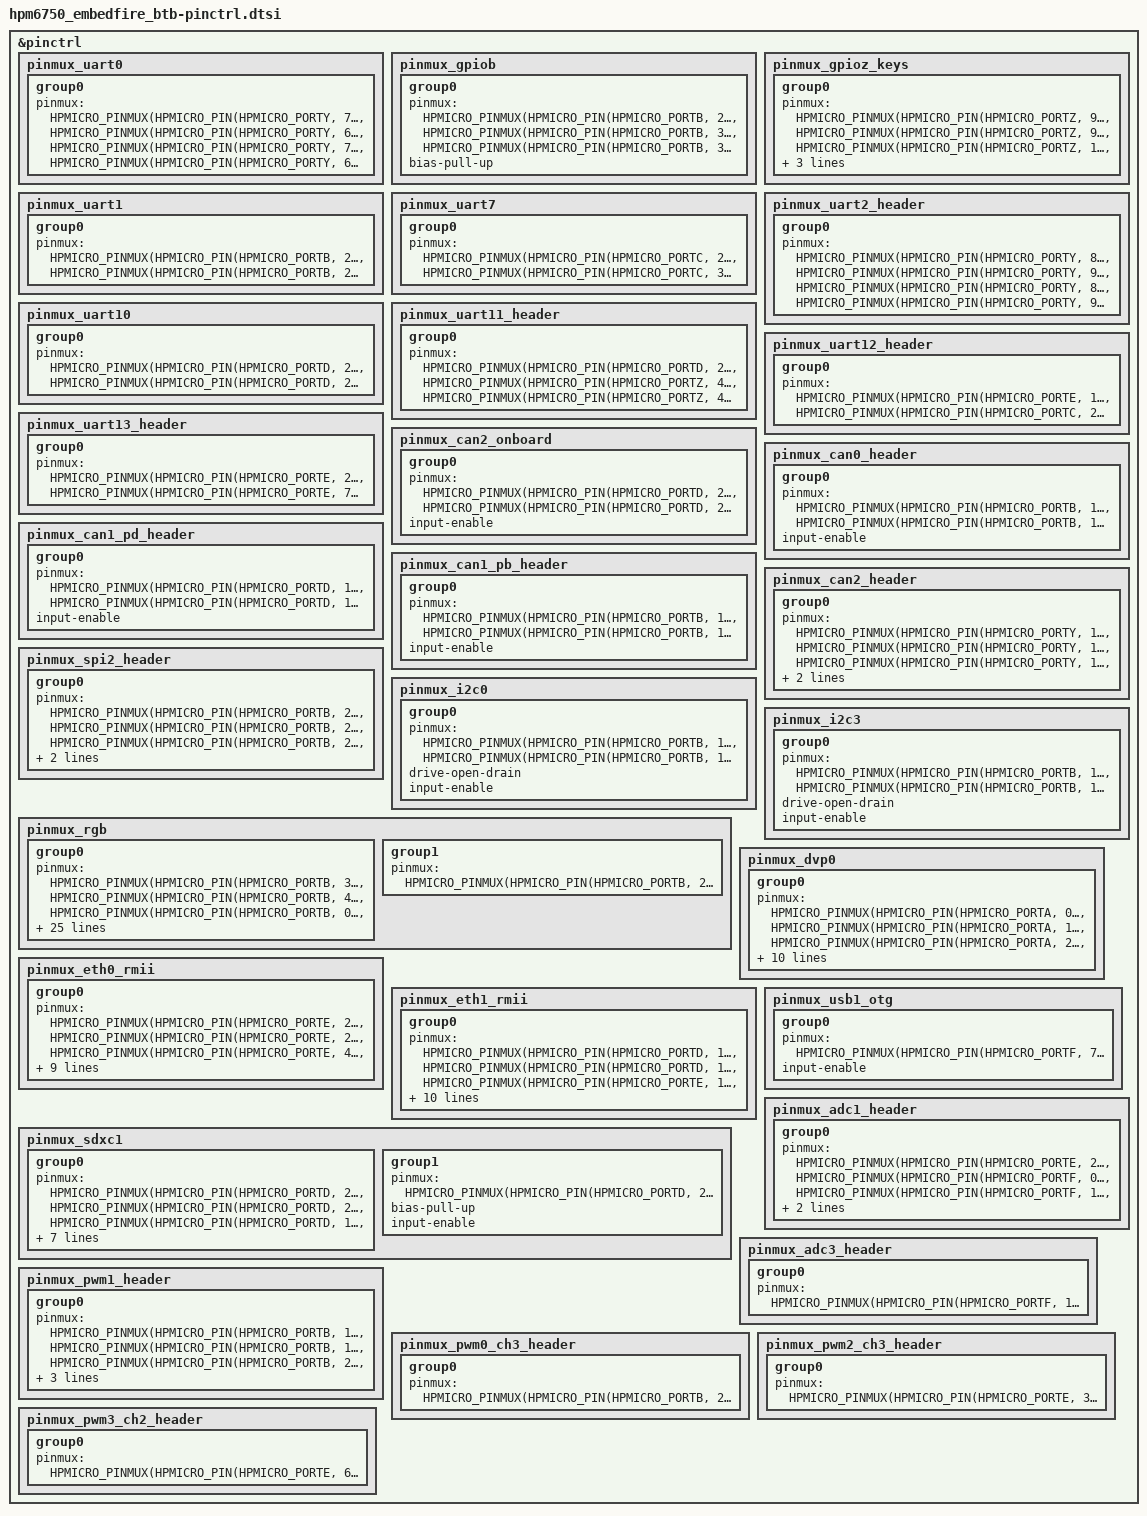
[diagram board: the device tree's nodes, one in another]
/* SPDX-License-Identifier: Apache-2.0 */

#include "dt-bindings/pinctrl/hpmicro-pinctrl-common.h"

&pinctrl {
	pinmux_uart0: pinmux_uart0 {
		group0 {
			pinmux = <HPMICRO_PINMUX(HPMICRO_PIN(HPMICRO_PORTY, 7), IOC_TYPE_IOC, 0, 2)>,
				 <HPMICRO_PINMUX(HPMICRO_PIN(HPMICRO_PORTY, 6), IOC_TYPE_IOC, 0, 2)>,
				 <HPMICRO_PINMUX(HPMICRO_PIN(HPMICRO_PORTY, 7), IOC_TYPE_PIOC, 0, 3)>,
				 <HPMICRO_PINMUX(HPMICRO_PIN(HPMICRO_PORTY, 6), IOC_TYPE_PIOC, 0, 3)>;
		};
	};

	pinmux_gpiob: pinmux_gpiob {
		group0 {
			pinmux = <HPMICRO_PINMUX(HPMICRO_PIN(HPMICRO_PORTB, 29), IOC_TYPE_IOC, 0, 0)>,
				 <HPMICRO_PINMUX(HPMICRO_PIN(HPMICRO_PORTB, 30), IOC_TYPE_IOC, 0, 0)>,
				 <HPMICRO_PINMUX(HPMICRO_PIN(HPMICRO_PORTB, 31), IOC_TYPE_IOC, 0, 0)>;
			bias-pull-up;
		};
	};

	pinmux_gpioz_keys: pinmux_gpioz_keys {
		group0 {
			pinmux = <HPMICRO_PINMUX(HPMICRO_PIN(HPMICRO_PORTZ, 9), IOC_TYPE_IOC, 0, 0)>,
				 <HPMICRO_PINMUX(HPMICRO_PIN(HPMICRO_PORTZ, 9), IOC_TYPE_BIOC, 0, 3)>,
				 <HPMICRO_PINMUX(HPMICRO_PIN(HPMICRO_PORTZ, 11), IOC_TYPE_IOC, 0, 0)>,
				 <HPMICRO_PINMUX(HPMICRO_PIN(HPMICRO_PORTZ, 11), IOC_TYPE_BIOC, 0, 3)>;
			bias-pull-up;
			input-enable;
		};
	};

	pinmux_uart1: pinmux_uart1 {
		group0 {
			pinmux = <HPMICRO_PINMUX(HPMICRO_PIN(HPMICRO_PORTB, 26), IOC_TYPE_IOC, 0, 2)>,
				 <HPMICRO_PINMUX(HPMICRO_PIN(HPMICRO_PORTB, 27), IOC_TYPE_IOC, 0, 2)>;
		};
	};

	pinmux_uart7: pinmux_uart7 {
		group0 {
			pinmux = <HPMICRO_PINMUX(HPMICRO_PIN(HPMICRO_PORTC, 2), IOC_TYPE_IOC, 0, 2)>,
				 <HPMICRO_PINMUX(HPMICRO_PIN(HPMICRO_PORTC, 3), IOC_TYPE_IOC, 0, 2)>;
		};
	};

	pinmux_uart2_header: pinmux_uart2_header {
		group0 {
			pinmux = <HPMICRO_PINMUX(HPMICRO_PIN(HPMICRO_PORTY, 8), IOC_TYPE_IOC, 0, 2)>,
				 <HPMICRO_PINMUX(HPMICRO_PIN(HPMICRO_PORTY, 9), IOC_TYPE_IOC, 0, 2)>,
				 <HPMICRO_PINMUX(HPMICRO_PIN(HPMICRO_PORTY, 8), IOC_TYPE_PIOC, 0, 3)>,
				 <HPMICRO_PINMUX(HPMICRO_PIN(HPMICRO_PORTY, 9), IOC_TYPE_PIOC, 0, 3)>;
		};
	};

	pinmux_uart10: pinmux_uart10 {
		group0 {
			pinmux = <HPMICRO_PINMUX(HPMICRO_PIN(HPMICRO_PORTD, 23), IOC_TYPE_IOC, 0, 2)>,
				 <HPMICRO_PINMUX(HPMICRO_PIN(HPMICRO_PORTD, 24), IOC_TYPE_IOC, 0, 2)>;
		};
	};

	pinmux_uart11_header: pinmux_uart11_header {
		group0 {
			pinmux = <HPMICRO_PINMUX(HPMICRO_PIN(HPMICRO_PORTD, 29), IOC_TYPE_IOC, 0, 2)>,
				 <HPMICRO_PINMUX(HPMICRO_PIN(HPMICRO_PORTZ, 4), IOC_TYPE_IOC, 0, 2)>,
				 <HPMICRO_PINMUX(HPMICRO_PIN(HPMICRO_PORTZ, 4), IOC_TYPE_BIOC, 0, 3)>;
		};
	};

	pinmux_uart12_header: pinmux_uart12_header {
		group0 {
			pinmux = <HPMICRO_PINMUX(HPMICRO_PIN(HPMICRO_PORTE, 1), IOC_TYPE_IOC, 0, 2)>,
				 <HPMICRO_PINMUX(HPMICRO_PIN(HPMICRO_PORTC, 20), IOC_TYPE_IOC, 0, 2)>;
		};
	};

	pinmux_uart13_header: pinmux_uart13_header {
		group0 {
			pinmux = <HPMICRO_PINMUX(HPMICRO_PIN(HPMICRO_PORTE, 2), IOC_TYPE_IOC, 0, 2)>,
				 <HPMICRO_PINMUX(HPMICRO_PIN(HPMICRO_PORTE, 7), IOC_TYPE_IOC, 0, 2)>;
		};
	};

	pinmux_can2_onboard: pinmux_can2_onboard {
		group0 {
			pinmux = <HPMICRO_PINMUX(HPMICRO_PIN(HPMICRO_PORTD, 20), IOC_TYPE_IOC, 0, 7)>,
				 <HPMICRO_PINMUX(HPMICRO_PIN(HPMICRO_PORTD, 25), IOC_TYPE_IOC, 0, 7)>;
			input-enable;
		};
	};

	pinmux_can0_header: pinmux_can0_header {
		group0 {
			pinmux = <HPMICRO_PINMUX(HPMICRO_PIN(HPMICRO_PORTB, 15), IOC_TYPE_IOC, 0, 7)>,
				 <HPMICRO_PINMUX(HPMICRO_PIN(HPMICRO_PORTB, 17), IOC_TYPE_IOC, 0, 7)>;
			input-enable;
		};
	};

	pinmux_can1_pd_header: pinmux_can1_pd_header {
		group0 {
			pinmux = <HPMICRO_PINMUX(HPMICRO_PIN(HPMICRO_PORTD, 16), IOC_TYPE_IOC, 0, 7)>,
				 <HPMICRO_PINMUX(HPMICRO_PIN(HPMICRO_PORTD, 19), IOC_TYPE_IOC, 0, 7)>;
			input-enable;
		};
	};

	pinmux_can1_pb_header: pinmux_can1_pb_header {
		group0 {
			pinmux = <HPMICRO_PINMUX(HPMICRO_PIN(HPMICRO_PORTB, 19), IOC_TYPE_IOC, 0, 7)>,
				 <HPMICRO_PINMUX(HPMICRO_PIN(HPMICRO_PORTB, 18), IOC_TYPE_IOC, 0, 7)>;
			input-enable;
		};
	};

	pinmux_can2_header: pinmux_can2_header {
		group0 {
			pinmux = <HPMICRO_PINMUX(HPMICRO_PIN(HPMICRO_PORTY, 10), IOC_TYPE_IOC, 0, 7)>,
				 <HPMICRO_PINMUX(HPMICRO_PIN(HPMICRO_PORTY, 11), IOC_TYPE_IOC, 0, 7)>,
				 <HPMICRO_PINMUX(HPMICRO_PIN(HPMICRO_PORTY, 10), IOC_TYPE_PIOC, 0, 3)>,
				 <HPMICRO_PINMUX(HPMICRO_PIN(HPMICRO_PORTY, 11), IOC_TYPE_PIOC, 0, 3)>;
			input-enable;
		};
	};

	pinmux_spi2_header: pinmux_spi2_header {
		group0 {
			pinmux = <HPMICRO_PINMUX(HPMICRO_PIN(HPMICRO_PORTB, 21), IOC_TYPE_IOC, 0, 5)>,
				 <HPMICRO_PINMUX(HPMICRO_PIN(HPMICRO_PORTB, 22), IOC_TYPE_IOC, 0, 5)>,
				 <HPMICRO_PINMUX(HPMICRO_PIN(HPMICRO_PORTB, 25), IOC_TYPE_IOC, 0, 5)>,
				 <HPMICRO_PINMUX(HPMICRO_PIN(HPMICRO_PORTB, 24), IOC_TYPE_IOC, 0, 0)>;
			input-enable;
		};
	};

	pinmux_i2c0: pinmux_i2c0 {
		group0 {
			pinmux = <HPMICRO_PINMUX(HPMICRO_PIN(HPMICRO_PORTB, 11), IOC_TYPE_IOC, 0, 4)>,
				 <HPMICRO_PINMUX(HPMICRO_PIN(HPMICRO_PORTB, 10), IOC_TYPE_IOC, 0, 4)>;
			drive-open-drain;
			input-enable;
		};
	};

	pinmux_i2c3: pinmux_i2c3 {
		group0 {
			pinmux = <HPMICRO_PINMUX(HPMICRO_PIN(HPMICRO_PORTB, 14), IOC_TYPE_IOC, 0, 4)>,
				 <HPMICRO_PINMUX(HPMICRO_PIN(HPMICRO_PORTB, 13), IOC_TYPE_IOC, 0, 4)>;
			drive-open-drain;
			input-enable;
		};
	};

	pinmux_rgb: pinmux_rgb {
		group0 {
			pinmux = <HPMICRO_PINMUX(HPMICRO_PIN(HPMICRO_PORTB, 3), IOC_TYPE_IOC, 0, 20)>,
				 <HPMICRO_PINMUX(HPMICRO_PIN(HPMICRO_PORTB, 4), IOC_TYPE_IOC, 0, 20)>,
				 <HPMICRO_PINMUX(HPMICRO_PIN(HPMICRO_PORTB, 0), IOC_TYPE_IOC, 0, 20)>,
				 <HPMICRO_PINMUX(HPMICRO_PIN(HPMICRO_PORTA, 31), IOC_TYPE_IOC, 0, 20)>,
				 <HPMICRO_PINMUX(HPMICRO_PIN(HPMICRO_PORTA, 26), IOC_TYPE_IOC, 0, 20)>,
				 <HPMICRO_PINMUX(HPMICRO_PIN(HPMICRO_PORTA, 21), IOC_TYPE_IOC, 0, 20)>,
				 <HPMICRO_PINMUX(HPMICRO_PIN(HPMICRO_PORTA, 27), IOC_TYPE_IOC, 0, 20)>,
				 <HPMICRO_PINMUX(HPMICRO_PIN(HPMICRO_PORTA, 28), IOC_TYPE_IOC, 0, 20)>,
				 <HPMICRO_PINMUX(HPMICRO_PIN(HPMICRO_PORTB, 6), IOC_TYPE_IOC, 0, 20)>,
				 <HPMICRO_PINMUX(HPMICRO_PIN(HPMICRO_PORTB, 1), IOC_TYPE_IOC, 0, 20)>,
				 <HPMICRO_PINMUX(HPMICRO_PIN(HPMICRO_PORTA, 22), IOC_TYPE_IOC, 0, 20)>,
				 <HPMICRO_PINMUX(HPMICRO_PIN(HPMICRO_PORTA, 23), IOC_TYPE_IOC, 0, 20)>,
				 <HPMICRO_PINMUX(HPMICRO_PIN(HPMICRO_PORTA, 29), IOC_TYPE_IOC, 0, 20)>,
				 <HPMICRO_PINMUX(HPMICRO_PIN(HPMICRO_PORTA, 24), IOC_TYPE_IOC, 0, 20)>,
				 <HPMICRO_PINMUX(HPMICRO_PIN(HPMICRO_PORTA, 30), IOC_TYPE_IOC, 0, 20)>,
				 <HPMICRO_PINMUX(HPMICRO_PIN(HPMICRO_PORTA, 25), IOC_TYPE_IOC, 0, 20)>,
				 <HPMICRO_PINMUX(HPMICRO_PIN(HPMICRO_PORTB, 5), IOC_TYPE_IOC, 0, 20)>,
				 <HPMICRO_PINMUX(HPMICRO_PIN(HPMICRO_PORTB, 7), IOC_TYPE_IOC, 0, 20)>,
				 <HPMICRO_PINMUX(HPMICRO_PIN(HPMICRO_PORTB, 2), IOC_TYPE_IOC, 0, 20)>,
				 <HPMICRO_PINMUX(HPMICRO_PIN(HPMICRO_PORTA, 16), IOC_TYPE_IOC, 0, 20)>,
				 <HPMICRO_PINMUX(HPMICRO_PIN(HPMICRO_PORTA, 12), IOC_TYPE_IOC, 0, 20)>,
				 <HPMICRO_PINMUX(HPMICRO_PIN(HPMICRO_PORTA, 17), IOC_TYPE_IOC, 0, 20)>,
				 <HPMICRO_PINMUX(HPMICRO_PIN(HPMICRO_PORTA, 13), IOC_TYPE_IOC, 0, 20)>,
				 <HPMICRO_PINMUX(HPMICRO_PIN(HPMICRO_PORTA, 18), IOC_TYPE_IOC, 0, 20)>,
				 <HPMICRO_PINMUX(HPMICRO_PIN(HPMICRO_PORTA, 20), IOC_TYPE_IOC, 0, 20)>,
				 <HPMICRO_PINMUX(HPMICRO_PIN(HPMICRO_PORTA, 15), IOC_TYPE_IOC, 0, 20)>,
				 <HPMICRO_PINMUX(HPMICRO_PIN(HPMICRO_PORTA, 19), IOC_TYPE_IOC, 0, 20)>,
				 <HPMICRO_PINMUX(HPMICRO_PIN(HPMICRO_PORTA, 14), IOC_TYPE_IOC, 0, 20)>;
		};

		group1 {
			pinmux = <HPMICRO_PINMUX(HPMICRO_PIN(HPMICRO_PORTB, 23), IOC_TYPE_IOC, 0, 0)>;
		};
	};

	pinmux_dvp0: pinmux_dvp0 {
		group0 {
			pinmux = <HPMICRO_PINMUX(HPMICRO_PIN(HPMICRO_PORTA, 0), IOC_TYPE_IOC, 0, 22)>,
				 <HPMICRO_PINMUX(HPMICRO_PIN(HPMICRO_PORTA, 1), IOC_TYPE_IOC, 0, 22)>,
				 <HPMICRO_PINMUX(HPMICRO_PIN(HPMICRO_PORTA, 2), IOC_TYPE_IOC, 0, 22)>,
				 <HPMICRO_PINMUX(HPMICRO_PIN(HPMICRO_PORTA, 3), IOC_TYPE_IOC, 0, 22)>,
				 <HPMICRO_PINMUX(HPMICRO_PIN(HPMICRO_PORTA, 4), IOC_TYPE_IOC, 0, 22)>,
				 <HPMICRO_PINMUX(HPMICRO_PIN(HPMICRO_PORTA, 5), IOC_TYPE_IOC, 0, 22)>,
				 <HPMICRO_PINMUX(HPMICRO_PIN(HPMICRO_PORTA, 6), IOC_TYPE_IOC, 0, 22)>,
				 <HPMICRO_PINMUX(HPMICRO_PIN(HPMICRO_PORTA, 7), IOC_TYPE_IOC, 0, 22)>,
				 <HPMICRO_PINMUX(HPMICRO_PIN(HPMICRO_PORTA, 8), IOC_TYPE_IOC, 0, 22)>,
				 <HPMICRO_PINMUX(HPMICRO_PIN(HPMICRO_PORTA, 9), IOC_TYPE_IOC, 0, 22)>,
				 <HPMICRO_PINMUX(HPMICRO_PIN(HPMICRO_PORTA, 10), IOC_TYPE_IOC, 0, 22)>,
				 <HPMICRO_PINMUX(HPMICRO_PIN(HPMICRO_PORTA, 11), IOC_TYPE_IOC, 0, 22)>;
			input-enable;
		};
	};

	pinmux_eth0_rmii: pinmux_eth0_rmii {
		group0 {
			pinmux = <HPMICRO_PINMUX(HPMICRO_PIN(HPMICRO_PORTE, 22), IOC_TYPE_IOC, 0, 19)>,
				 <HPMICRO_PINMUX(HPMICRO_PIN(HPMICRO_PORTE, 23), IOC_TYPE_IOC, 0, 19)>,
				 <HPMICRO_PINMUX(HPMICRO_PIN(HPMICRO_PORTE, 4), IOC_TYPE_IOC, 0, 18)>,
				 <HPMICRO_PINMUX(HPMICRO_PIN(HPMICRO_PORTE, 28), IOC_TYPE_IOC, 0, 18)>,
				 <HPMICRO_PINMUX(HPMICRO_PIN(HPMICRO_PORTD, 31), IOC_TYPE_IOC, 0, 18)>,
				 <HPMICRO_PINMUX(HPMICRO_PIN(HPMICRO_PORTE, 26), IOC_TYPE_IOC, 0, 18)>,
				 <HPMICRO_PINMUX(HPMICRO_PIN(HPMICRO_PORTD, 30), IOC_TYPE_IOC, 0, 18)>,
				 <HPMICRO_PINMUX(HPMICRO_PIN(HPMICRO_PORTE, 27), IOC_TYPE_IOC, 0, 18)>,
				 <HPMICRO_PINMUX(HPMICRO_PIN(HPMICRO_PORTE, 31), IOC_TYPE_IOC, 0, 18)>,
				 <HPMICRO_PINMUX(HPMICRO_PIN(HPMICRO_PORTE, 29), IOC_TYPE_IOC, 0, 0)>;
			input-schmitt-enable;
			drive-strength = "r000";
		};
	};

	pinmux_eth1_rmii: pinmux_eth1_rmii {
		group0 {
			pinmux = <HPMICRO_PINMUX(HPMICRO_PIN(HPMICRO_PORTD, 11), IOC_TYPE_IOC, 0, 19)>,
				 <HPMICRO_PINMUX(HPMICRO_PIN(HPMICRO_PORTD, 14), IOC_TYPE_IOC, 0, 19)>,
				 <HPMICRO_PINMUX(HPMICRO_PIN(HPMICRO_PORTE, 18), IOC_TYPE_IOC, 0, 18)>,
				 <HPMICRO_PINMUX(HPMICRO_PIN(HPMICRO_PORTE, 19), IOC_TYPE_IOC, 0, 18)>,
				 <HPMICRO_PINMUX(HPMICRO_PIN(HPMICRO_PORTE, 20), IOC_TYPE_IOC, 0, 18)>,
				 <HPMICRO_PINMUX(HPMICRO_PIN(HPMICRO_PORTE, 14), IOC_TYPE_IOC, 0, 18)>,
				 <HPMICRO_PINMUX(HPMICRO_PIN(HPMICRO_PORTE, 15), IOC_TYPE_IOC, 0, 18)>,
				 <HPMICRO_PINMUX(HPMICRO_PIN(HPMICRO_PORTE, 17), IOC_TYPE_IOC, 0, 18)>,
				 <HPMICRO_PINMUX(HPMICRO_PIN(HPMICRO_PORTE, 16), IOC_TYPE_IOC, 0, 18)>,
				 <HPMICRO_PINMUX(HPMICRO_PIN(HPMICRO_PORTE, 24), IOC_TYPE_IOC, 0, 0)>;
			input-schmitt-enable;
			input-enable;
			drive-strength = "r000";
		};
	};

	pinmux_sdxc1: pinmux_sdxc1 {
		group0 {
			pinmux = <HPMICRO_PINMUX(HPMICRO_PIN(HPMICRO_PORTD, 21), IOC_TYPE_IOC, 0, 17)>,
				 <HPMICRO_PINMUX(HPMICRO_PIN(HPMICRO_PORTD, 22), IOC_TYPE_IOC, 0, 17)>,
				 <HPMICRO_PINMUX(HPMICRO_PIN(HPMICRO_PORTD, 18), IOC_TYPE_IOC, 0, 17)>,
				 <HPMICRO_PINMUX(HPMICRO_PIN(HPMICRO_PORTD, 17), IOC_TYPE_IOC, 0, 17)>,
				 <HPMICRO_PINMUX(HPMICRO_PIN(HPMICRO_PORTD, 27), IOC_TYPE_IOC, 0, 17)>,
				 <HPMICRO_PINMUX(HPMICRO_PIN(HPMICRO_PORTD, 26), IOC_TYPE_IOC, 0, 17)>;
			bias-pull-up;
			input-enable;
			power-source = "3v3";
			drive-strength = "r110";
		};

		group1 {
			pinmux = <HPMICRO_PINMUX(HPMICRO_PIN(HPMICRO_PORTD, 28), IOC_TYPE_IOC, 0, 0)>;
			bias-pull-up;
			input-enable;
		};
	};

	pinmux_usb1_otg: pinmux_usb1_otg {
		group0 {
			pinmux = <HPMICRO_PINMUX(HPMICRO_PIN(HPMICRO_PORTF, 7), IOC_TYPE_IOC, 0, 24)>;
			input-enable;
		};
	};

	pinmux_adc1_header: pinmux_adc1_header {
		group0 {
			pinmux = <HPMICRO_PINMUX(HPMICRO_PIN(HPMICRO_PORTE, 25), IOC_TYPE_IOC, 1, 0)>,
				 <HPMICRO_PINMUX(HPMICRO_PIN(HPMICRO_PORTF, 0), IOC_TYPE_IOC, 1, 0)>,
				 <HPMICRO_PINMUX(HPMICRO_PIN(HPMICRO_PORTF, 1), IOC_TYPE_IOC, 1, 0)>,
				 <HPMICRO_PINMUX(HPMICRO_PIN(HPMICRO_PORTF, 2), IOC_TYPE_IOC, 1, 0)>,
				 <HPMICRO_PINMUX(HPMICRO_PIN(HPMICRO_PORTF, 4), IOC_TYPE_IOC, 1, 0)>;
		};
	};

	pinmux_adc3_header: pinmux_adc3_header {
		group0 {
			pinmux = <HPMICRO_PINMUX(HPMICRO_PIN(HPMICRO_PORTF, 10), IOC_TYPE_IOC, 1, 0)>;
		};
	};

	pinmux_pwm1_header: pinmux_pwm1_header {
		group0 {
			pinmux = <HPMICRO_PINMUX(HPMICRO_PIN(HPMICRO_PORTB, 19), IOC_TYPE_IOC, 0, 16)>,
				 <HPMICRO_PINMUX(HPMICRO_PIN(HPMICRO_PORTB, 18), IOC_TYPE_IOC, 0, 16)>,
				 <HPMICRO_PINMUX(HPMICRO_PIN(HPMICRO_PORTB, 22), IOC_TYPE_IOC, 0, 16)>,
				 <HPMICRO_PINMUX(HPMICRO_PIN(HPMICRO_PORTB, 21), IOC_TYPE_IOC, 0, 16)>,
				 <HPMICRO_PINMUX(HPMICRO_PIN(HPMICRO_PORTB, 25), IOC_TYPE_IOC, 0, 16)>,
				 <HPMICRO_PINMUX(HPMICRO_PIN(HPMICRO_PORTB, 24), IOC_TYPE_IOC, 0, 16)>;
		};
	};

	pinmux_pwm0_ch3_header: pinmux_pwm0_ch3_header {
		group0 {
			pinmux = <HPMICRO_PINMUX(HPMICRO_PIN(HPMICRO_PORTB, 28), IOC_TYPE_IOC, 0, 16)>;
		};
	};

	pinmux_pwm2_ch3_header: pinmux_pwm2_ch3_header {
		group0 {
			pinmux = <HPMICRO_PINMUX(HPMICRO_PIN(HPMICRO_PORTE, 3), IOC_TYPE_IOC, 0, 16)>;
		};
	};

	pinmux_pwm3_ch2_header: pinmux_pwm3_ch2_header {
		group0 {
			pinmux = <HPMICRO_PINMUX(HPMICRO_PIN(HPMICRO_PORTE, 6), IOC_TYPE_IOC, 0, 16)>;
		};
	};
};

